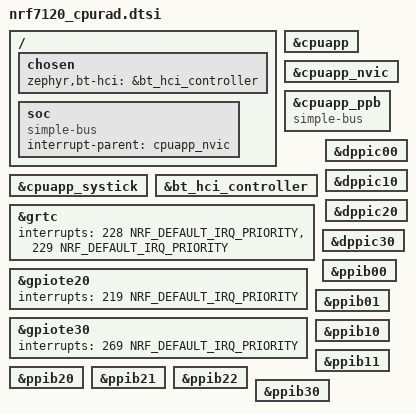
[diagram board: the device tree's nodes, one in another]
/*
 * Copyright (c) 2025 Nordic Semiconductor ASA
 *
 * SPDX-License-Identifier: Apache-2.0
 */

/*
 * NOTE: This file is created to add Bluetooth Controller support for nRF7120.
 * Since nRF7120 currently only has cpuapp and cpuflpr (no separate cpurad CPU),
 * this file configures BT controller support on the cpuapp which has access
 * to the radio peripheral.
 */

#include <nordic/nrf7120_enga.dtsi>

cpu: &cpuapp {};

systick: &cpuapp_systick {};

nvic: &cpuapp_nvic {};

/delete-node/ &cpuflpr;
/delete-node/ &cpuflpr_clic;

/ {
	chosen {
		zephyr,bt-hci = &bt_hci_controller;
	};

	soc {
		compatible = "simple-bus";
		interrupt-parent = <&cpuapp_nvic>;
		ranges;
	};
};

&cpuapp_ppb {
	compatible = "simple-bus";
	ranges;
};

&bt_hci_controller {
	status = "okay";
};

&grtc {
	interrupts = <228 NRF_DEFAULT_IRQ_PRIORITY>,
		     /* Reserved for Zero Latency IRQs */
		     <229 NRF_DEFAULT_IRQ_PRIORITY>;
};

&gpiote20 {
	interrupts = <219 NRF_DEFAULT_IRQ_PRIORITY>;
};

&gpiote30 {
	interrupts = <269 NRF_DEFAULT_IRQ_PRIORITY>;
};

&dppic00 {
	status = "okay";
};

&dppic10 {
	status = "okay";
};

&dppic20 {
	status = "okay";
};

&dppic30 {
	status = "okay";
};

&ppib00 {
	status = "okay";
};

&ppib01 {
	status = "okay";
};

&ppib10 {
	status = "okay";
};

&ppib11 {
	status = "okay";
};

&ppib20 {
	status = "okay";
};

&ppib21 {
	status = "okay";
};

&ppib22 {
	status = "okay";
};

&ppib30 {
	status = "okay";
};
